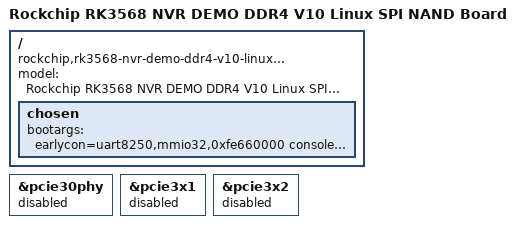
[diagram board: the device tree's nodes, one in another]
// SPDX-License-Identifier: (GPL-2.0+ OR MIT)
/*
 * Copyright (c) 2021 Rockchip Electronics Co., Ltd.
 */

/dts-v1/;

#include "rk3568-nvr-demo-v10.dtsi"
#include "rk3568-nvr-linux.dtsi"

/ {
	model = "Rockchip RK3568 NVR DEMO DDR4 V10 Linux SPI NAND Board";
	compatible = "rockchip,rk3568-nvr-demo-ddr4-v10-linux-spi-nand", "rockchip,rk3568";

	chosen {
		bootargs = "earlycon=uart8250,mmio32,0xfe660000 console=ttyFIQ0 ubi.mtd=3 root=ubi0:rootfs rootfstype=ubifs";
	};

};

&pcie30phy {
	status = "disabled";
};

&pcie3x1 {
	status = "disabled";
};

&pcie3x2 {
	status = "disabled";
};
